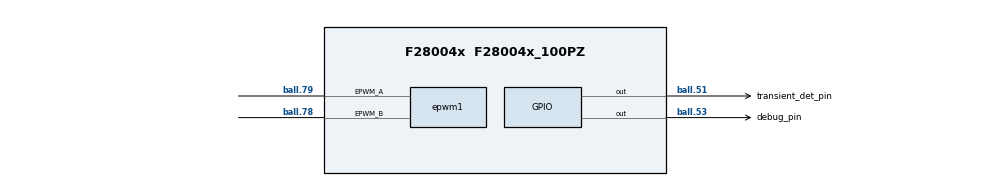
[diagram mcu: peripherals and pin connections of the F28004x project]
/**
 * @cliArgs --device "F28004x" --package "F28004x_100PZ" --part "F28004x_100PZ" --context "system" --product "C2000WARE@4.03.00.00"
 * @versions {"tool":"1.15.0+2826"}
 */

/**
 * Import the modules used in this configuration.
 */
const adc              = scripting.addModule("/driverlib/adc.js", {}, false);
const adc1             = adc.addInstance();
const adc2             = adc.addInstance();
const asysctl          = scripting.addModule("/driverlib/asysctl.js");
const cla              = scripting.addModule("/driverlib/cla.js", {}, false);
const cla1             = cla.addInstance();
const cputimer         = scripting.addModule("/driverlib/cputimer.js", {}, false);
const cputimer1        = cputimer.addInstance();
const dac              = scripting.addModule("/driverlib/dac.js", {}, false);
const dac1             = dac.addInstance();
const dma              = scripting.addModule("/driverlib/dma.js", {}, false);
const dma1             = dma.addInstance();
const dma2             = dma.addInstance();
const epwm             = scripting.addModule("/driverlib/epwm.js");
const epwm1            = epwm.addInstance();
const epwm2            = epwm.addInstance();
const epwm3            = epwm.addInstance();
const epwm4            = epwm.addInstance();
const gpio             = scripting.addModule("/driverlib/gpio.js", {}, false);
const gpio1            = gpio.addInstance();
const gpio2            = gpio.addInstance();
const inputxbar_input  = scripting.addModule("/driverlib/inputxbar_input.js", {}, false);
const inputxbar_input1 = inputxbar_input.addInstance();
const memcfg           = scripting.addModule("/driverlib/memcfg.js");
const FPUfastRTS       = scripting.addModule("/libraries/math/FPUfastRTS/FPUfastRTS.js", {}, false);
const FPUfastRTS1      = FPUfastRTS.addInstance();

/**
 * Write custom configuration values to the imported modules.
 */
adc1.$name                          = "myADC0";
adc1.soc0UseCalculatedSampleTime    = true;
adc1.soc0UseSampleTimeCalculator    = true;
adc1.soc1UseSampleTimeCalculator    = true;
adc1.soc1UseCalculatedSampleTime    = true;
adc1.soc6Trigger                    = "ADC_TRIGGER_EPWM1_SOCB";
adc1.soc5Trigger                    = "ADC_TRIGGER_EPWM1_SOCB";
adc1.soc7Trigger                    = "ADC_TRIGGER_EPWM1_SOCB";
adc1.soc8Trigger                    = "ADC_TRIGGER_EPWM1_SOCB";
adc1.soc9Trigger                    = "ADC_TRIGGER_EPWM1_SOCB";
adc1.interruptCycleOffset           = 10;
adc1.interruptPulseMode             = "ADC_PULSE_END_OF_CONV";
adc1.interrupt2SOCSource            = "ADC_SOC_NUMBER1";
adc1.enableInterrupt1               = true;
adc1.enableInterrupt1ContinuousMode = true;
adc1.enabledInts                    = ["ADC_INT_NUMBER1"];
adc1.soc2Trigger                    = "ADC_TRIGGER_EPWM3_SOCA";
adc1.soc2UseSampleTimeCalculator    = true;
adc1.soc2UseCalculatedSampleTime    = true;
adc1.soc3UseSampleTimeCalculator    = true;
adc1.soc3UseCalculatedSampleTime    = true;
adc1.soc0Trigger                    = "ADC_TRIGGER_EPWM3_SOCA";
adc1.soc0Name                       = "Vin";
adc1.soc1Name                       = "Iin";
adc1.soc1Trigger                    = "ADC_TRIGGER_EPWM3_SOCA";
adc1.soc2Name                       = "Iout1";
adc1.enabledSOCs                    = ["ADC_SOC_NUMBER0","ADC_SOC_NUMBER1","ADC_SOC_NUMBER2","ADC_SOC_NUMBER3"];
adc1.soc3Name                       = "Iout2";
adc1.soc3Trigger                    = "ADC_TRIGGER_EPWM3_SOCB";
adc1.interrupt1SOCSource            = "ADC_SOC_NUMBER3";
adc1.soc1Channel                    = "ADC_CH_ADCIN3";
adc1.soc2Channel                    = "ADC_CH_ADCIN6";
adc1.soc3Channel                    = "ADC_CH_ADCIN6";

adc2.$name                          = "myADC1";
adc2.adcBase                        = "ADCC_BASE";
adc2.soc0UseSampleTimeCalculator    = true;
adc2.soc0UseCalculatedSampleTime    = true;
adc2.soc1UseSampleTimeCalculator    = true;
adc2.soc1UseCalculatedSampleTime    = true;
adc2.soc2UseSampleTimeCalculator    = true;
adc2.soc2UseCalculatedSampleTime    = true;
adc2.soc3UseSampleTimeCalculator    = true;
adc2.soc3UseCalculatedSampleTime    = true;
adc2.soc4UseSampleTimeCalculator    = true;
adc2.soc4UseCalculatedSampleTime    = true;
adc2.soc5UseSampleTimeCalculator    = true;
adc2.soc5UseCalculatedSampleTime    = true;
adc2.interruptPulseMode             = "ADC_PULSE_END_OF_CONV";
adc2.enableInterrupt1               = true;
adc2.enableInterrupt3               = true;
adc2.enableInterrupt1ContinuousMode = true;
adc2.socHighPriorityMode            = "ADC_PRI_THRU_SOC5_HIPRI";
adc2.enableInterrupt2               = true;
adc2.enableInterrupt2ContinuousMode = true;
adc2.soc6Name                       = "Vo3";
adc2.soc6Channel                    = "ADC_CH_ADCIN14";
adc2.soc6Trigger                    = "ADC_TRIGGER_EPWM3_SOCA";
adc2.soc6UseSampleTimeCalculator    = true;
adc2.soc6UseCalculatedSampleTime    = true;
adc2.soc7Name                       = "Vo4";
adc2.soc7Channel                    = "ADC_CH_ADCIN14";
adc2.soc7Trigger                    = "ADC_TRIGGER_EPWM3_SOCA";
adc2.soc7UseSampleTimeCalculator    = true;
adc2.soc7UseCalculatedSampleTime    = true;
adc2.soc4Name                       = "Vo1";
adc2.soc4Channel                    = "ADC_CH_ADCIN14";
adc2.soc4Trigger                    = "ADC_TRIGGER_EPWM3_SOCA";
adc2.soc5Name                       = "Vo2";
adc2.soc5Channel                    = "ADC_CH_ADCIN14";
adc2.interrupt2SOCSource            = "ADC_SOC_NUMBER7";
adc2.soc0Trigger                    = "ADC_TRIGGER_EPWM3_SOCA";
adc2.soc3Trigger                    = "ADC_TRIGGER_EPWM3_SOCB";
adc2.soc5Trigger                    = "ADC_TRIGGER_EPWM3_SOCB";
adc2.enabledInts                    = ["ADC_INT_NUMBER1"];
adc2.soc1Trigger                    = "ADC_TRIGGER_EPWM3_SOCA";
adc2.soc2Channel                    = "ADC_CH_ADCIN14";
adc2.soc3Name                       = "Vo2";
adc2.soc3Channel                    = "ADC_CH_ADCIN14";
adc2.soc0Name                       = "Il";
adc2.soc0Channel                    = "ADC_CH_ADCIN1";
adc2.soc1Name                       = "Vout1";
adc2.soc1Channel                    = "ADC_CH_ADCIN14";
adc2.soc2Name                       = "Vout2";
adc2.soc2Trigger                    = "ADC_TRIGGER_EPWM3_SOCB";
adc2.enabledSOCs                    = ["ADC_SOC_NUMBER0","ADC_SOC_NUMBER1","ADC_SOC_NUMBER2"];
adc2.interrupt1SOCSource            = "ADC_SOC_NUMBER2";

asysctl.analogReference        = "INTERNAL";
asysctl.analogReferenceVoltage = "1P65";

cla1.$name              = "myCLA0";
cla1.enable_CLA_TASK_4  = false;
cla1.enable_CLA_TASK_5  = false;
cla1.enable_CLA_TASK_6  = false;
cla1.enable_CLA_TASK_7  = false;
cla1.enable_CLA_TASK_8  = false;
cla1.cpuint_CLA_TASK_2  = false;
cla1.cpuint_CLA_TASK_3  = false;
cla1.cpuint_CLA_TASK_4  = false;
cla1.cpuint_CLA_TASK_8  = false;
cla1.cpuint_CLA_TASK_7  = false;
cla1.cpuint_CLA_TASK_6  = false;
cla1.cpuint_CLA_TASK_5  = false;
cla1.enable_CLA_TASK_3  = false;
cla1.trigger_CLA_TASK_1 = "CLA_TRIGGER_XINT1";
cla1.enable_CLA_TASK_2  = false;

cputimer1.$name          = "myCPUTIMER0";
cputimer1.emulationMode  = "CPUTIMER_EMULATIONMODE_RUNFREE";
cputimer1.timerPrescaler = 99;
cputimer1.timerPeriod    = 9999;

dac1.$name            = "L_out_val";
dac1.dacBase          = "DACB_BASE";
dac1.enableOutput     = true;
dac1.referenceVoltage = "DAC_REF_ADC_VREFHI";
dac1.gainMode         = "DAC_GAIN_TWO";

dma1.$name                = "myDMA0";
dma1.enableTriggers       = true;
dma1.continuousModeConfig = "DMA_CFG_CONTINUOUS_ENABLE";
dma1.startChannel         = true;
dma1.srcAddressInputMode  = "VARIABLE";
dma1.destAddressInputMode = "VARIABLE";
dma1.triggerSource        = "DMA_TRIGGER_ADCC1";
dma1.srcAddressVariable   = "ADCC0_Result_base";
dma1.destAddressVariable  = "ADCC0_results_add";
dma1.registerInterrupts   = true;
dma1.enableInterrupts     = true;
dma1.interruptMode        = "DMA_INT_AT_END";
dma1.srcBurstStep         = 1;
dma1.destBurstStep        = 1;
dma1.transferSize         = 2;
dma1.destWrapSize         = 2;
dma1.destTransferStep     = 1;
dma1.burstSize            = 3;
dma1.srcTransferStep      = -2;
dma1.destWrapStep         = -5;

dma2.$name                  = "myDMA1";
dma2.enableTriggers         = true;
dma2.triggerSource          = "DMA_TRIGGER_ADCA1";
dma2.continuousModeConfig   = "DMA_CFG_CONTINUOUS_ENABLE";
dma2.srcAddressInputMode    = "VARIABLE";
dma2.srcAddressVariable     = "ADCA0_Result_base";
dma2.destAddressInputMode   = "VARIABLE";
dma2.destAddressVariable    = "ADCA0_results_add";
dma2.startChannel           = true;
dma2.dmaBase                = "DMA_CH2_BASE";
dma2.transferSize           = 2;
dma2.destWrapSize           = 2;
dma2.destTransferStep       = 1;
dma2.destBurstStep          = 1;
dma2.burstSize              = 4;
dma2.srcBurstStep           = 1;
dma2.srcTransferStep        = -3;
dma2.destWrapStep           = -7;
dma2.useInterrupts          = true;
dma2.registerInterrupts     = true;
dma2.enableInterrupts       = true;
dma2.dmaInt.enableInterrupt = true;

epwm.enableInfo    = true;
epwm.enableWarning = true;

epwm1.generateCodeTemplate                                       = true;
epwm1.$name                                                      = "ControlPWM";
epwm1.epwmCounterCompare_enableShadowLoadModeCMPB                = false;
epwm1.epwmDeadband_polarityFED                                   = "EPWM_DB_POLARITY_ACTIVE_LOW";
epwm1.epwmTimebase_hsClockDiv                                    = "EPWM_HSCLOCK_DIVIDER_1";
epwm1.epwmActionQualifier_t1Source                               = "EPWM_AQ_TRIGGER_EVENT_TRIG_EPWM_SYNCIN";
epwm1.epwmActionQualifier_t2Source                               = "EPWM_AQ_TRIGGER_EVENT_TRIG_EPWM_SYNCIN";
epwm1.epwmActionQualifier_continousSwForceReloadModeGld          = true;
epwm1.epwmCounterCompare_enableShadowLoadModeCMPA                = false;
epwm1.useInterfacePins                                           = ["EPWM#_A"];
epwm1.epwmTimebase_emulationMode                                 = "EPWM_EMULATION_FREE_RUN";
epwm1.epwmTimebase_periodGld                                     = true;
epwm1.epwmTimebase_counterMode                                   = "EPWM_COUNTER_MODE_UP_DOWN";
epwm1.hrpwm_enable                                               = true;
epwm1.hrpwm_autoConv                                             = true;
epwm1.hrpwm_enableCalculator                                     = true;
epwm1.epwmDeadband_delayRED                                      = 20;
epwm1.epwmDeadband_delayFED                                      = 20;
epwm1.epwmActionQualifier_continousSwForceReloadMode             = "EPWM_AQ_SW_IMMEDIATE_LOAD";
epwm1.epwmTimebase_counterModeAfterSync                          = "EPWM_COUNT_MODE_UP_AFTER_SYNC";
epwm1.epwmActionQualifier_EPWM_AQ_OUTPUT_A_ON_TIMEBASE_UP_CMPA   = "EPWM_AQ_OUTPUT_HIGH";
epwm1.epwmActionQualifier_EPWM_AQ_OUTPUT_A_ON_TIMEBASE_DOWN_CMPA = "EPWM_AQ_OUTPUT_LOW";
epwm1.epwmActionQualifier_EPWM_AQ_OUTPUT_A_ON_T1_COUNT_UP        = "EPWM_AQ_OUTPUT_LOW";
epwm1.epwmActionQualifier_EPWM_AQ_OUTPUT_B_ON_TIMEBASE_UP_CMPA   = "EPWM_AQ_OUTPUT_LOW";
epwm1.epwmActionQualifier_EPWM_AQ_OUTPUT_B_ON_TIMEBASE_DOWN_CMPA = "EPWM_AQ_OUTPUT_HIGH";
epwm1.epwmDeadband_enableRED                                     = true;
epwm1.epwmDeadband_enableFED                                     = true;
epwm1.epwmActionQualifier_EPWM_AQ_OUTPUT_B_ON_T1_COUNT_UP        = "EPWM_AQ_OUTPUT_HIGH";
epwm1.hrpwm_syncSource                                           = "HRPWM_PWMSYNC_SOURCE_ZERO";
epwm1.epwmTimebase_syncOutPulseMode                              = "EPWM_SYNC_OUT_PULSE_ON_COUNTER_ZERO";
epwm1.epwmTimebase_period                                        = 1000;
epwm1.epwmCounterCompare_cmpA                                    = 500;
epwm1.epwmCounterCompare_cmpB                                    = 999;
epwm1.epwmTripZone_EPWM_TZ_ACTION_EVENT_TZA                      = "EPWM_TZ_ACTION_LOW";
epwm1.epwmTripZone_EPWM_TZ_ACTION_EVENT_TZB                      = "EPWM_TZ_ACTION_LOW";
epwm1.epwm.$assign                                               = "EPWM1";
epwm1.epwm.epwm_aPin.$assign                                     = "ball.79";
epwm1.epwm.epwm_bPin.$assign                                     = "ball.78";

epwm2.epwmActionQualifier_EPWM_AQ_OUTPUT_B_ON_TIMEBASE_UP_CMPA   = "EPWM_AQ_OUTPUT_LOW";
epwm2.epwmActionQualifier_EPWM_AQ_OUTPUT_B_ON_TIMEBASE_DOWN_CMPA = "EPWM_AQ_OUTPUT_HIGH";
epwm2.epwmActionQualifier_EPWM_AQ_OUTPUT_B_ON_T1_COUNT_UP        = "EPWM_AQ_OUTPUT_HIGH";
epwm2.epwmDeadband_delayRED                                      = 20;
epwm2.epwmDeadband_delayFED                                      = 20;
epwm2.useInterfacePins                                           = ["EPWM#_A"];
epwm2.epwmTimebase_emulationMode                                 = "EPWM_EMULATION_FREE_RUN";
epwm2.epwmTimebase_hsClockDiv                                    = "EPWM_HSCLOCK_DIVIDER_1";
epwm2.epwmTimebase_periodGld                                     = true;
epwm2.epwmTimebase_counterMode                                   = "EPWM_COUNTER_MODE_UP_DOWN";
epwm2.epwmTimebase_counterModeAfterSync                          = "EPWM_COUNT_MODE_UP_AFTER_SYNC";
epwm2.epwmCounterCompare_enableShadowLoadModeCMPA                = false;
epwm2.epwmCounterCompare_enableShadowLoadModeCMPB                = false;
epwm2.epwmActionQualifier_continousSwForceReloadModeGld          = true;
epwm2.epwmActionQualifier_continousSwForceReloadMode             = "EPWM_AQ_SW_IMMEDIATE_LOAD";
epwm2.epwmActionQualifier_t1Source                               = "EPWM_AQ_TRIGGER_EVENT_TRIG_EPWM_SYNCIN";
epwm2.epwmActionQualifier_t2Source                               = "EPWM_AQ_TRIGGER_EVENT_TRIG_EPWM_SYNCIN";
epwm2.epwmActionQualifier_EPWM_AQ_OUTPUT_A_ON_TIMEBASE_UP_CMPA   = "EPWM_AQ_OUTPUT_HIGH";
epwm2.epwmActionQualifier_EPWM_AQ_OUTPUT_A_ON_TIMEBASE_DOWN_CMPA = "EPWM_AQ_OUTPUT_LOW";
epwm2.epwmActionQualifier_EPWM_AQ_OUTPUT_A_ON_T1_COUNT_UP        = "EPWM_AQ_OUTPUT_LOW";
epwm2.epwmDeadband_polarityFED                                   = "EPWM_DB_POLARITY_ACTIVE_LOW";
epwm2.epwmDeadband_enableRED                                     = true;
epwm2.epwmDeadband_enableFED                                     = true;
epwm2.hrpwm_enable                                               = true;
epwm2.hrpwm_autoConv                                             = true;
epwm2.hrpwm_enableCalculator                                     = true;
epwm2.$name                                                      = "ControlPWM_fixed_fsw";
epwm2.copyFrom                                                   = "ControlPWM";
epwm2.hrpwm_syncSource                                           = "HRPWM_PWMSYNC_SOURCE_ZERO";
epwm2.epwmTimebase_syncOutPulseMode                              = "EPWM_SYNC_OUT_PULSE_ON_COUNTER_ZERO";
epwm2.epwmEventTrigger_enableInterrupt                           = true;
epwm2.epwmEventTrigger_registerInterrupts                        = true;
epwm2.epwmEventTrigger_interruptSource                           = "EPWM_INT_TBCTR_U_CMPB";
epwm2.epwmEventTrigger_interruptEventCount                       = "1";
epwm2.epwmEventTrigger_interruptEventCountInitForce              = true;
epwm2.epwmTimebase_period                                        = 1000;
epwm2.epwmCounterCompare_cmpA                                    = 500;
epwm2.epwmCounterCompare_cmpB                                    = 999;
epwm2.epwm.$assign                                               = "EPWM2";
epwm2.epwmInt.enableInterrupt                                    = true;

epwm3.epwmTimebase_emulationMode                                 = "EPWM_EMULATION_FREE_RUN";
epwm3.epwmTimebase_hsClockDiv                                    = "EPWM_HSCLOCK_DIVIDER_1";
epwm3.epwmTimebase_periodGld                                     = true;
epwm3.epwmTimebase_counterMode                                   = "EPWM_COUNTER_MODE_UP_DOWN";
epwm3.epwmTimebase_counterModeAfterSync                          = "EPWM_COUNT_MODE_UP_AFTER_SYNC";
epwm3.epwmTimebase_syncOutPulseMode                              = "EPWM_SYNC_OUT_PULSE_ON_EPWMxSYNCIN";
epwm3.hrpwm_syncSource                                           = "HRPWM_PWMSYNC_SOURCE_ZERO";
epwm3.epwmCounterCompare_enableShadowLoadModeCMPA                = false;
epwm3.epwmCounterCompare_enableShadowLoadModeCMPB                = false;
epwm3.epwmActionQualifier_continousSwForceReloadModeGld          = true;
epwm3.epwmActionQualifier_continousSwForceReloadMode             = "EPWM_AQ_SW_IMMEDIATE_LOAD";
epwm3.epwmActionQualifier_t1Source                               = "EPWM_AQ_TRIGGER_EVENT_TRIG_EPWM_SYNCIN";
epwm3.epwmActionQualifier_t2Source                               = "EPWM_AQ_TRIGGER_EVENT_TRIG_EPWM_SYNCIN";
epwm3.epwmActionQualifier_EPWM_AQ_OUTPUT_A_ON_TIMEBASE_UP_CMPA   = "EPWM_AQ_OUTPUT_HIGH";
epwm3.epwmActionQualifier_EPWM_AQ_OUTPUT_A_ON_TIMEBASE_DOWN_CMPA = "EPWM_AQ_OUTPUT_LOW";
epwm3.epwmActionQualifier_EPWM_AQ_OUTPUT_A_ON_T1_COUNT_UP        = "EPWM_AQ_OUTPUT_LOW";
epwm3.epwmActionQualifier_EPWM_AQ_OUTPUT_B_ON_TIMEBASE_UP_CMPA   = "EPWM_AQ_OUTPUT_HIGH";
epwm3.epwmActionQualifier_EPWM_AQ_OUTPUT_B_ON_TIMEBASE_DOWN_CMPA = "EPWM_AQ_OUTPUT_LOW";
epwm3.epwmDeadband_polarityFED                                   = "EPWM_DB_POLARITY_ACTIVE_LOW";
epwm3.epwmDeadband_enableRED                                     = true;
epwm3.epwmDeadband_enableFED                                     = true;
epwm3.epwmEventTrigger_EPWM_SOC_A_triggerEnable                  = true;
epwm3.epwmEventTrigger_EPWM_SOC_A_triggerEventPrescalar          = "1";
epwm3.hrpwm_enable                                               = true;
epwm3.hrpwm_autoConv                                             = true;
epwm3.hrpwm_enableCalculator                                     = true;
epwm3.copyFrom                                                   = "ControlPWM_2fsw";
epwm3.$name                                                      = "ControlPWM_2fsw";
epwm3.epwmEventTrigger_EPWM_SOC_B_triggerEnable                  = true;
epwm3.epwmEventTrigger_EPWM_SOC_B_triggerEventPrescalar          = "1";
epwm3.epwmDeadband_delayRED                                      = 20;
epwm3.epwmDeadband_delayFED                                      = 20;
epwm3.epwmTimebase_period                                        = 500;
epwm3.epwmCounterCompare_cmpA                                    = 250;
epwm3.epwmCounterCompare_cmpB                                    = 499;
epwm3.epwmEventTrigger_EPWM_SOC_A_triggerSource                  = "EPWM_SOC_TBCTR_U_CMPB";
epwm3.epwmEventTrigger_EPWM_SOC_B_triggerSource                  = "EPWM_SOC_TBCTR_ZERO";

epwm4.$name                                                      = "fault_sw";
epwm4.epwmTimebase_emulationMode                                 = "EPWM_EMULATION_FREE_RUN";
epwm4.epwmTimebase_hsClockDiv                                    = "EPWM_HSCLOCK_DIVIDER_1";
epwm4.epwmTimebase_periodLoadMode                                = "EPWM_PERIOD_DIRECT_LOAD";
epwm4.epwmTimebase_period                                        = 1000;
epwm4.epwmTimebase_periodGld                                     = true;
epwm4.epwmTimebase_counterMode                                   = "EPWM_COUNTER_MODE_UP_DOWN";
epwm4.epwmTimebase_counterModeAfterSync                          = "EPWM_COUNT_MODE_UP_AFTER_SYNC";
epwm4.epwmTimebase_syncOutPulseMode                              = "EPWM_SYNC_OUT_PULSE_ON_COUNTER_ZERO";
epwm4.hrpwm_syncSource                                           = "HRPWM_PWMSYNC_SOURCE_ZERO";
epwm4.epwmCounterCompare_cmpA                                    = 500;
epwm4.epwmCounterCompare_cmpB                                    = 999;
epwm4.epwmCounterCompare_enableShadowLoadModeCMPA                = false;
epwm4.epwmCounterCompare_enableShadowLoadModeCMPB                = false;
epwm4.epwmActionQualifier_continousSwForceReloadModeGld          = true;
epwm4.epwmActionQualifier_continousSwForceReloadMode             = "EPWM_AQ_SW_IMMEDIATE_LOAD";
epwm4.epwmActionQualifier_t1Source                               = "EPWM_AQ_TRIGGER_EVENT_TRIG_EPWM_SYNCIN";
epwm4.epwmActionQualifier_t2Source                               = "EPWM_AQ_TRIGGER_EVENT_TRIG_EPWM_SYNCIN";
epwm4.epwmActionQualifier_EPWM_AQ_OUTPUT_A_ON_TIMEBASE_UP_CMPA   = "EPWM_AQ_OUTPUT_HIGH";
epwm4.epwmActionQualifier_EPWM_AQ_OUTPUT_A_ON_TIMEBASE_DOWN_CMPA = "EPWM_AQ_OUTPUT_LOW";
epwm4.epwmActionQualifier_EPWM_AQ_OUTPUT_B_ON_TIMEBASE_UP_CMPA   = "EPWM_AQ_OUTPUT_LOW";
epwm4.epwmActionQualifier_EPWM_AQ_OUTPUT_B_ON_TIMEBASE_DOWN_CMPA = "EPWM_AQ_OUTPUT_HIGH";
epwm4.epwmDeadband_enableRED                                     = true;
epwm4.epwmDeadband_enableFED                                     = true;
epwm4.epwmDeadband_polarityFED                                   = "EPWM_DB_POLARITY_ACTIVE_LOW";
epwm4.epwmDeadband_delayRED                                      = 20;
epwm4.epwmDeadband_delayFED                                      = 20;
epwm4.epwmEventTrigger_enableInterrupt                           = true;
epwm4.epwmEventTrigger_registerInterrupts                        = true;
epwm4.epwmEventTrigger_interruptSource                           = "EPWM_INT_TBCTR_U_CMPB";
epwm4.epwmEventTrigger_interruptEventCount                       = "1";
epwm4.epwm.$assign                                               = "EPWM6";
epwm4.epwmInt.enableInterrupt                                    = true;

gpio1.$name             = "debug_pin";
gpio1.writeInitialValue = true;
gpio1.direction         = "GPIO_DIR_MODE_OUT";
gpio1.gpioPin.$assign   = "ball.53";

gpio2.direction                 = "GPIO_DIR_MODE_OUT";
gpio2.useInterrupt              = true;
gpio2.$name                     = "transient_det_pin";
gpio2.writeInitialValue         = true;
gpio2.gpioPin.$assign           = "ball.51";
gpio2.xint.intType              = "GPIO_INT_TYPE_RISING_EDGE";
gpio2.xint.enableInt            = true;
gpio2.xint.registerInterrupts   = true;
gpio2.xint.xInt.enableInterrupt = true;

inputxbar_input1.$name         = "myINPUTXBARINPUT0";
gpio2.xint.inputxbar           = inputxbar_input1;
inputxbar_input1.inputxbarGpio = "GPIO12";

memcfg.config_MEMCFG_SECT_LS0 = "CLA_prog";
memcfg.config_MEMCFG_SECT_LS2 = "CLA_data";
memcfg.config_MEMCFG_SECT_LS3 = "CLA_data";
memcfg.config_MEMCFG_SECT_LS4 = "CLA_prog";

FPUfastRTS1.$name = "myFFR0";

/**
 * Pinmux solution for unlocked pins/peripherals. This ensures that minor changes to the automatic solver in a future
 * version of the tool will not impact the pinmux you originally saw.  These lines can be completely deleted in order to
 * re-solve from scratch.
 */
epwm2.epwm.epwm_aPin.$suggestSolution = "ball.77";
epwm2.epwm.epwm_bPin.$suggestSolution = "ball.76";
epwm3.epwm.$suggestSolution           = "EPWM3";
epwm3.epwm.epwm_aPin.$suggestSolution = "ball.75";
epwm3.epwm.epwm_bPin.$suggestSolution = "ball.89";
epwm4.epwm.epwm_aPin.$suggestSolution = "ball.93";
epwm4.epwm.epwm_bPin.$suggestSolution = "ball.52";
